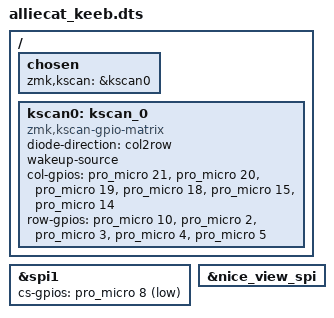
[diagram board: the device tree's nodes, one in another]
/*
 * Copyright (c) 2024 The ZMK Contributors
 *
 * SPDX-License-Identifier: MIT
 */

/ {
    chosen {
        zmk,kscan = &kscan0;
    };

    kscan0: kscan_0 {
        compatible = "zmk,kscan-gpio-matrix";
        diode-direction = "col2row";
        wakeup-source;

        col-gpios
            = <&pro_micro 21 GPIO_ACTIVE_HIGH>
            , <&pro_micro 20 GPIO_ACTIVE_HIGH>
            , <&pro_micro 19 GPIO_ACTIVE_HIGH>
            , <&pro_micro 18 GPIO_ACTIVE_HIGH>
            , <&pro_micro 15 GPIO_ACTIVE_HIGH>
            , <&pro_micro 14 GPIO_ACTIVE_HIGH>
            ;

        row-gpios
            = <&pro_micro 10 GPIO_ACTIVE_HIGH>
            , <&pro_micro 2 GPIO_ACTIVE_HIGH>
            , <&pro_micro 3 GPIO_ACTIVE_HIGH>
            , <&pro_micro 4 GPIO_ACTIVE_HIGH>
            , <&pro_micro 5 GPIO_ACTIVE_HIGH>
            ;
    };
};

&spi1 {
    status = "okay";

    cs-gpios
        = <&pro_micro 8 GPIO_ACTIVE_LOW>
        ;
};

&nice_view_spi {
    status = "okay";
};
